# SERDES0 register map
Vendor: Texas Instruments
Peripheral module from a debugger description file (folder am65x).
Registers are 32-bit, read-write, reset 0x0 unless marked. A register's access mark holds for its fields unless they carry their own. Offsets are as the file gives them; lines under a group give offsets from that group; [hi:lo] are bit positions; {n}, {i} and the like mark numbered series; 'fields as' and 'values as' point back to an identical list; <NAME> marks a mode.

## SERDES0 (part 1 of 2)
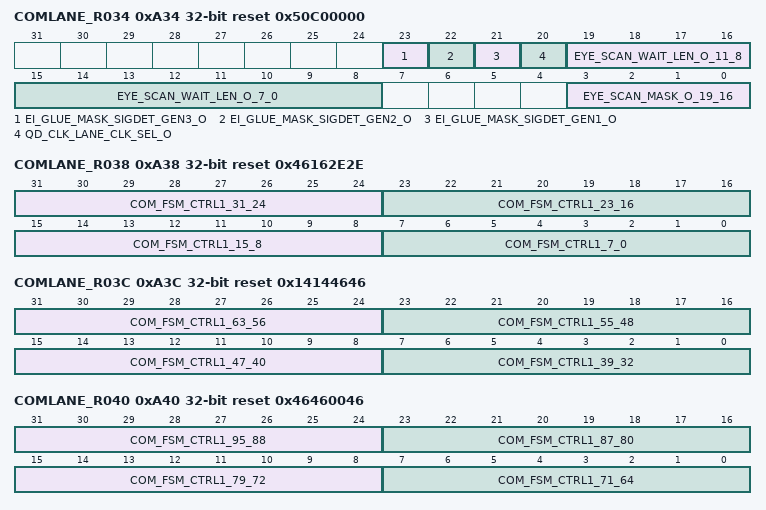
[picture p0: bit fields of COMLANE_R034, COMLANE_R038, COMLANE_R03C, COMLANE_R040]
0xA34 COMLANE_R034 reset 0x50C00000 — The comlane_034 register
  [23] EI_GLUE_MASK_SIGDET_GEN3_O — Mask bits for Gen3 rate for EI Infererence
  [22] EI_GLUE_MASK_SIGDET_GEN2_O — Mask bits for Gen2 rate for EI Infererence
  [21] EI_GLUE_MASK_SIGDET_GEN1_O — Mask bits for Gen1 rate for EI Infererence
  [20] QD_CLK_LANE_CLK_SEL_O — Selects quad clock for Tx Mux 2 and Rx Mux 4
  [19:16] EYE_SCAN_WAIT_LEN_O_11_8 — Eye scan wait time
  [15:8] EYE_SCAN_WAIT_LEN_O_7_0 — Eye scan wait time
  [3:0] EYE_SCAN_MASK_O_19_16 — Mask eye scan results
0xA38 COMLANE_R038 reset 0x46162E2E — The comlane_038 register
  [31:24] COM_FSM_CTRL1_31_24 — COMLANE FSM control 1 register 31-24
  [23:16] COM_FSM_CTRL1_23_16 — COMLANE FSM control 1 register 23-16
  [15:8] COM_FSM_CTRL1_15_8 — COMLANE FSM control 1 register 15-8
  [7:0] COM_FSM_CTRL1_7_0 — COMLANE FSM control 1 register 7-0
0xA3C COMLANE_R03C reset 0x14144646 — The comlane_03c register
  [31:24] COM_FSM_CTRL1_63_56 — COMLANE FSM control 1 register 63-56
  [23:16] COM_FSM_CTRL1_55_48 — COMLANE FSM control 1 register 55-48
  [15:8] COM_FSM_CTRL1_47_40 — COMLANE FSM control 1 register 47-40
  [7:0] COM_FSM_CTRL1_39_32 — COMLANE FSM control 1 register 39-32
0xA40 COMLANE_R040 reset 0x46460046 — The comlane_040 register
  [31:24] COM_FSM_CTRL1_95_88 — COMLANE FSM control 1 register 95-88
  [23:16] COM_FSM_CTRL1_87_80 — COMLANE FSM control 1 register 87-80
  [15:8] COM_FSM_CTRL1_79_72 — COMLANE FSM control 1 register 79-72
  [7:0] COM_FSM_CTRL1_71_64 — COMLANE FSM control 1 register 71-64
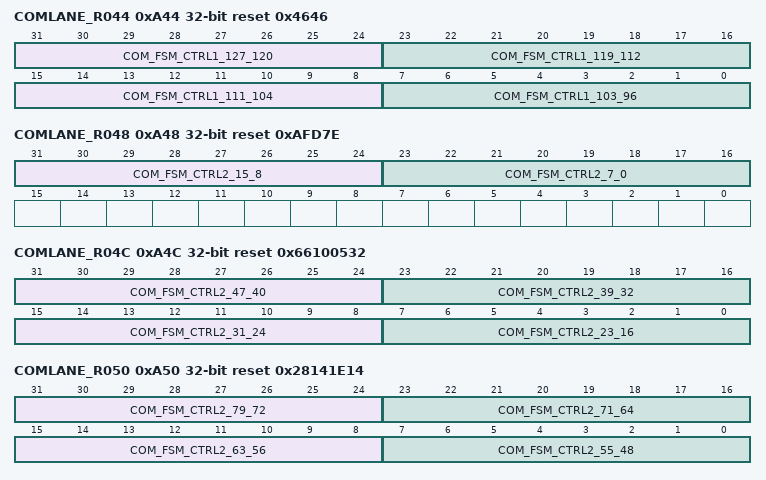
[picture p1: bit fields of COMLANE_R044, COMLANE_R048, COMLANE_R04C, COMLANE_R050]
0xA44 COMLANE_R044 reset 0x4646 — The comlane_044 register
  [31:24] COM_FSM_CTRL1_127_120 — COMLANE FSM control 1 register 127-120
  [23:16] COM_FSM_CTRL1_119_112 — COMLANE FSM control 1 register 119-112
  [15:8] COM_FSM_CTRL1_111_104 — COMLANE FSM control 1 register 111-104
  [7:0] COM_FSM_CTRL1_103_96 — COMLANE FSM control 1 register 103-96
0xA48 COMLANE_R048 reset 0xAFD7E — The comlane_048 register
  [31:24] COM_FSM_CTRL2_15_8 — COMLANE FSM control 2 register [15:8]
  [23:16] COM_FSM_CTRL2_7_0 — COMLANE FSM control 2 register [7:0]
0xA4C COMLANE_R04C reset 0x66100532 — The comlane_04c register
  [31:24] COM_FSM_CTRL2_47_40 — COMLANE FSM control 2 register
  [23:16] COM_FSM_CTRL2_39_32 — COMLANE FSM control 2 register
  [15:8] COM_FSM_CTRL2_31_24 — COMLANE FSM control 2 register
  [7:0] COM_FSM_CTRL2_23_16 — COMLANE FSM control 2 register
0xA50 COMLANE_R050 reset 0x28141E14 — The comlane_050 register
  [31:24] COM_FSM_CTRL2_79_72 — COMLANE FSM control 2 register
  [23:16] COM_FSM_CTRL2_71_64 — COMLANE FSM control 2 register
  [15:8] COM_FSM_CTRL2_63_56 — COMLANE FSM control 2 register
  [7:0] COM_FSM_CTRL2_55_48 — COMLANE FSM control 2 register
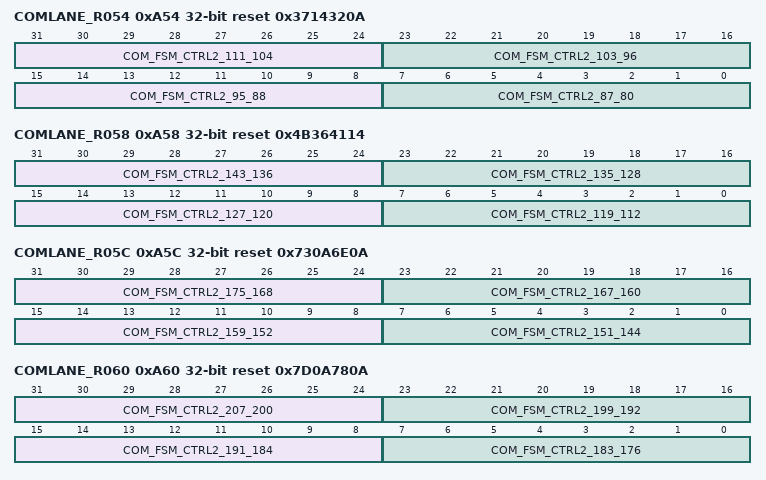
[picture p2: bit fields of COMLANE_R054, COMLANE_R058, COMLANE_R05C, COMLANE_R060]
0xA54 COMLANE_R054 reset 0x3714320A — The comlane_054 register
  [31:24] COM_FSM_CTRL2_111_104 — COMLANE FSM control 2 register
  [23:16] COM_FSM_CTRL2_103_96 — COMLANE FSM control 2 register
  [15:8] COM_FSM_CTRL2_95_88 — COMLANE FSM control 2 register
  [7:0] COM_FSM_CTRL2_87_80 — COMLANE FSM control 2 register
0xA58 COMLANE_R058 reset 0x4B364114 — The comlane_058 register
  [31:24] COM_FSM_CTRL2_143_136 — COMLANE FSM control 2 register
  [23:16] COM_FSM_CTRL2_135_128 — COMLANE FSM control 2 register
  [15:8] COM_FSM_CTRL2_127_120 — COMLANE FSM control 2 register
  [7:0] COM_FSM_CTRL2_119_112 — COMLANE FSM control 2 register
0xA5C COMLANE_R05C reset 0x730A6E0A — The comlane_05c register
  [31:24] COM_FSM_CTRL2_175_168 — COMLANE FSM control 2 register
  [23:16] COM_FSM_CTRL2_167_160 — COMLANE FSM control 2 register
  [15:8] COM_FSM_CTRL2_159_152 — COMLANE FSM control 2 register
  [7:0] COM_FSM_CTRL2_151_144 — COMLANE FSM control 2 register
0xA60 COMLANE_R060 reset 0x7D0A780A — The comlane_060 register
  [31:24] COM_FSM_CTRL2_207_200 — COMLANE FSM control 2 register
  [23:16] COM_FSM_CTRL2_199_192 — COMLANE FSM control 2 register
  [15:8] COM_FSM_CTRL2_191_184 — COMLANE FSM control 2 register
  [7:0] COM_FSM_CTRL2_183_176 — COMLANE FSM control 2 register
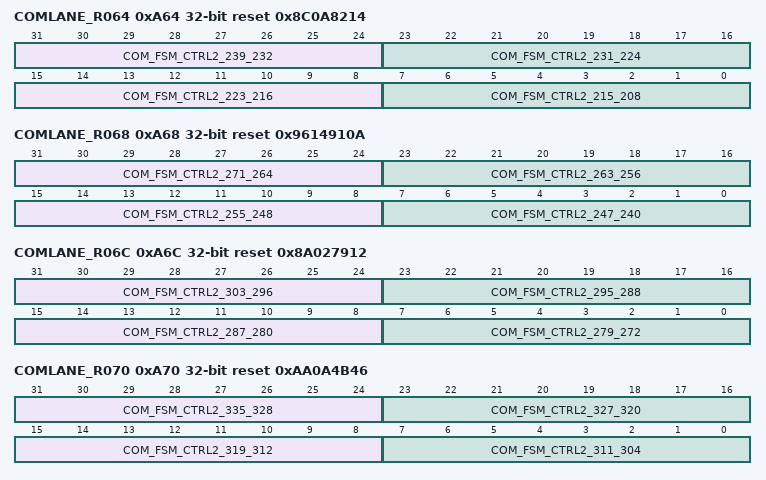
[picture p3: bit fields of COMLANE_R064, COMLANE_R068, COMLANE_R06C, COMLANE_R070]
0xA64 COMLANE_R064 reset 0x8C0A8214 — The comlane_064 register
  [31:24] COM_FSM_CTRL2_239_232 — COMLANE FSM control 2 register
  [23:16] COM_FSM_CTRL2_231_224 — COMLANE FSM control 2 register
  [15:8] COM_FSM_CTRL2_223_216 — COMLANE FSM control 2 register
  [7:0] COM_FSM_CTRL2_215_208 — COMLANE FSM control 2 register
0xA68 COMLANE_R068 reset 0x9614910A — The comlane_068 register
  [31:24] COM_FSM_CTRL2_271_264 — COMLANE FSM control 2 register
  [23:16] COM_FSM_CTRL2_263_256 — COMLANE FSM control 2 register
  [15:8] COM_FSM_CTRL2_255_248 — COMLANE FSM control 2 register
  [7:0] COM_FSM_CTRL2_247_240 — COMLANE FSM control 2 register
0xA6C COMLANE_R06C reset 0x8A027912 — The comlane_06c register
  [31:24] COM_FSM_CTRL2_303_296 — COMLANE FSM control 2 register
  [23:16] COM_FSM_CTRL2_295_288 — COMLANE FSM control 2 register
  [15:8] COM_FSM_CTRL2_287_280 — COMLANE FSM control 2 register
  [7:0] COM_FSM_CTRL2_279_272 — COMLANE FSM control 2 register
0xA70 COMLANE_R070 reset 0xAA0A4B46 — The comlane_070 register
  [31:24] COM_FSM_CTRL2_335_328 — COMLANE FSM control 2 register
  [23:16] COM_FSM_CTRL2_327_320 — COMLANE FSM control 2 register
  [15:8] COM_FSM_CTRL2_319_312 — COMLANE FSM control 2 register
  [7:0] COM_FSM_CTRL2_311_304 — COMLANE FSM control 2 register
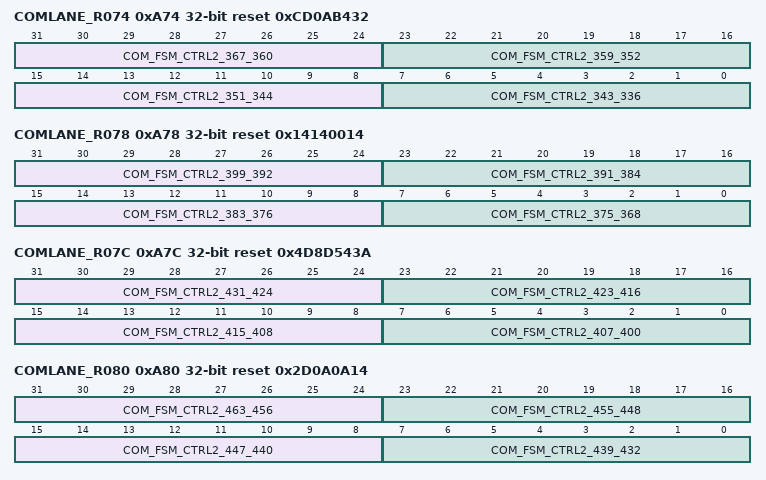
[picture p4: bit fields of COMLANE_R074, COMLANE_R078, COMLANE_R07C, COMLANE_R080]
0xA74 COMLANE_R074 reset 0xCD0AB432 — The comlane_074 register
  [31:24] COM_FSM_CTRL2_367_360 — COMLANE FSM control 2 register
  [23:16] COM_FSM_CTRL2_359_352 — COMLANE FSM control 2 register
  [15:8] COM_FSM_CTRL2_351_344 — COMLANE FSM control 2 register
  [7:0] COM_FSM_CTRL2_343_336 — COMLANE FSM control 2 register
0xA78 COMLANE_R078 reset 0x14140014 — The comlane_078 register
  [31:24] COM_FSM_CTRL2_399_392 — COMLANE FSM control 2 register
  [23:16] COM_FSM_CTRL2_391_384 — COMLANE FSM control 2 register
  [15:8] COM_FSM_CTRL2_383_376 — COMLANE FSM control 2 register
  [7:0] COM_FSM_CTRL2_375_368 — COMLANE FSM control 2 register
0xA7C COMLANE_R07C reset 0x4D8D543A — The comlane_07c register
  [31:24] COM_FSM_CTRL2_431_424 — COMLANE FSM control 2 register
  [23:16] COM_FSM_CTRL2_423_416 — COMLANE FSM control 2 register
  [15:8] COM_FSM_CTRL2_415_408 — COMLANE FSM control 2 register
  [7:0] COM_FSM_CTRL2_407_400 — COMLANE FSM control 2 register
0xA80 COMLANE_R080 reset 0x2D0A0A14 — The comlane_080 register
  [31:24] COM_FSM_CTRL2_463_456 — COMLANE FSM control 2 register
  [23:16] COM_FSM_CTRL2_455_448 — COMLANE FSM control 2 register
  [15:8] COM_FSM_CTRL2_447_440 — COMLANE FSM control 2 register
  [7:0] COM_FSM_CTRL2_439_432 — COMLANE FSM control 2 register
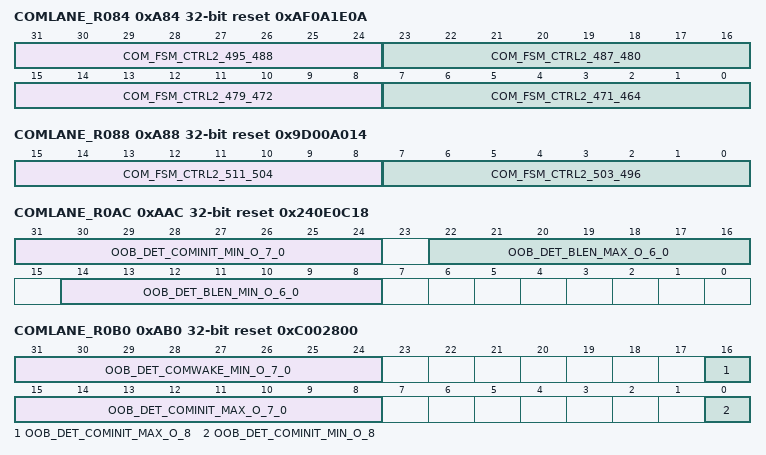
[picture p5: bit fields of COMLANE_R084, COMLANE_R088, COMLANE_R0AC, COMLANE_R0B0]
0xA84 COMLANE_R084 reset 0xAF0A1E0A — The comlane_084 register
  [31:24] COM_FSM_CTRL2_495_488 — COMLANE FSM control 2 register
  [23:16] COM_FSM_CTRL2_487_480 — COMLANE FSM control 2 register
  [15:8] COM_FSM_CTRL2_479_472 — COMLANE FSM control 2 register
  [7:0] COM_FSM_CTRL2_471_464 — COMLANE FSM control 2 register
0xA88 COMLANE_R088 reset 0x9D00A014 — The comlane_088 register
  [15:8] COM_FSM_CTRL2_511_504 — COMLANE FSM control 2 register
  [7:0] COM_FSM_CTRL2_503_496 — COMLANE FSM control 2 register
0xAAC COMLANE_R0AC reset 0x240E0C18 — The comlane_0ac register
  [31:24] OOB_DET_COMINIT_MIN_O_7_0 — OOB detector COMINIT maximum idle length.
  [22:16] OOB_DET_BLEN_MAX_O_6_0 — OOB detector maximum burst length.
  [14:8] OOB_DET_BLEN_MIN_O_6_0 — OOB detector minimum burst length.
0xAB0 COMLANE_R0B0 reset 0xC002800 — The comlane_0b0 register
  [31:24] OOB_DET_COMWAKE_MIN_O_7_0 — OOB detector COMWAKE minimum idle length.
  [16] OOB_DET_COMINIT_MAX_O_8 — OOB detector COMINIT maximum idle length.
  [15:8] OOB_DET_COMINIT_MAX_O_7_0 — OOB detector COMINIT maximum idle length.
  [0] OOB_DET_COMINIT_MIN_O_8 — OOB detector COMINIT maximum idle length.
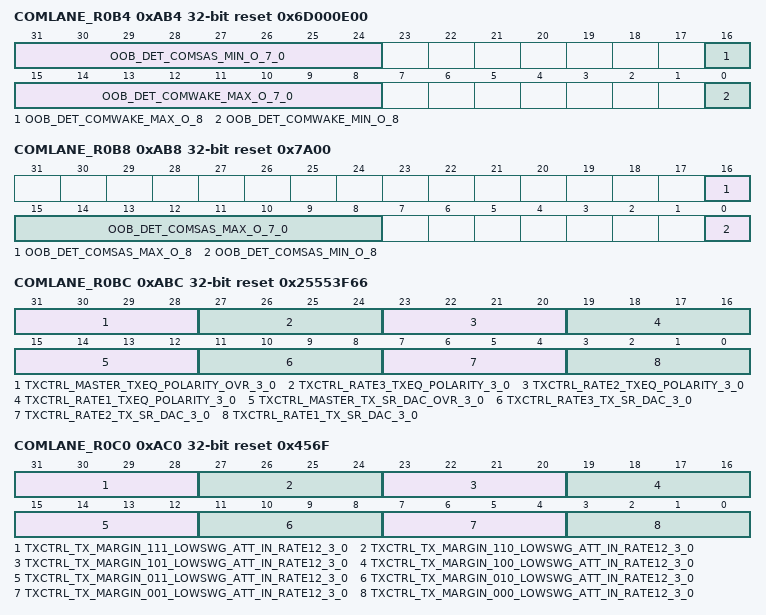
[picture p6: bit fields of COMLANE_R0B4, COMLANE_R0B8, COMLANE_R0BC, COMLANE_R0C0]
0xAB4 COMLANE_R0B4 reset 0x6D000E00 — The comlane_0b4 register
  [31:24] OOB_DET_COMSAS_MIN_O_7_0 — OOB detector COMSAS maximum idle length.
  [16] OOB_DET_COMWAKE_MAX_O_8 — OOB detector COMWAKE maximum idle length.
  [15:8] OOB_DET_COMWAKE_MAX_O_7_0 — OOB detector COMWAKE maximum idle length.
  [0] OOB_DET_COMWAKE_MIN_O_8 — OOB detector COMWAKE minimum idle length.
0xAB8 COMLANE_R0B8 reset 0x7A00 — The comlane_0b8 register
  [16] OOB_DET_COMSAS_MAX_O_8 — OOB detector COMSAS maximum idle length.
  [15:8] OOB_DET_COMSAS_MAX_O_7_0 — OOB detector COMSAS maximum idle length.
  [0] OOB_DET_COMSAS_MIN_O_8 — OOB detector COMSAS maximum idle length.
0xABC COMLANE_R0BC reset 0x25553F66 — The comlane_0bc register
  [31:28] TXCTRL_MASTER_TXEQ_POLARITY_OVR_3_0 — TX master coefficient polarity overrides.
  [27:24] TXCTRL_RATE3_TXEQ_POLARITY_3_0 — TX rate3 coefficent polarity
  [23:20] TXCTRL_RATE2_TXEQ_POLARITY_3_0 — TX rate2 coefficent polarity
  [19:16] TXCTRL_RATE1_TXEQ_POLARITY_3_0 — TX rate1 coefficent polarity
  [15:12] TXCTRL_MASTER_TX_SR_DAC_OVR_3_0 — TX master slew rate DAC overrides
  [11:8] TXCTRL_RATE3_TX_SR_DAC_3_0 — TX rate3 slew rate DAC setting
  [7:4] TXCTRL_RATE2_TX_SR_DAC_3_0 — TX rate2 slew rate DAC setting
  [3:0] TXCTRL_RATE1_TX_SR_DAC_3_0 — TX rate1 slew rate DAC setting
0xAC0 COMLANE_R0C0 reset 0x456F — The comlane_0c0 register
  [31:28] TXCTRL_TX_MARGIN_111_LOWSWG_ATT_IN_RATE12_3_0 — PIPE tx_margin low swing setting
  [27:24] TXCTRL_TX_MARGIN_110_LOWSWG_ATT_IN_RATE12_3_0 — PIPE tx_margin low swing setting
  [23:20] TXCTRL_TX_MARGIN_101_LOWSWG_ATT_IN_RATE12_3_0 — PIPE tx_margin low swing setting
  [19:16] TXCTRL_TX_MARGIN_100_LOWSWG_ATT_IN_RATE12_3_0 — PIPE tx_margin low swing setting
  [15:12] TXCTRL_TX_MARGIN_011_LOWSWG_ATT_IN_RATE12_3_0 — PIPE tx_margin low swing setting
  [11:8] TXCTRL_TX_MARGIN_010_LOWSWG_ATT_IN_RATE12_3_0 — PIPE tx_margin low swing setting
  [7:4] TXCTRL_TX_MARGIN_001_LOWSWG_ATT_IN_RATE12_3_0 — PIPE tx_margin low swing setting
  [3:0] TXCTRL_TX_MARGIN_000_LOWSWG_ATT_IN_RATE12_3_0 — PIPE tx_margin low swing setting
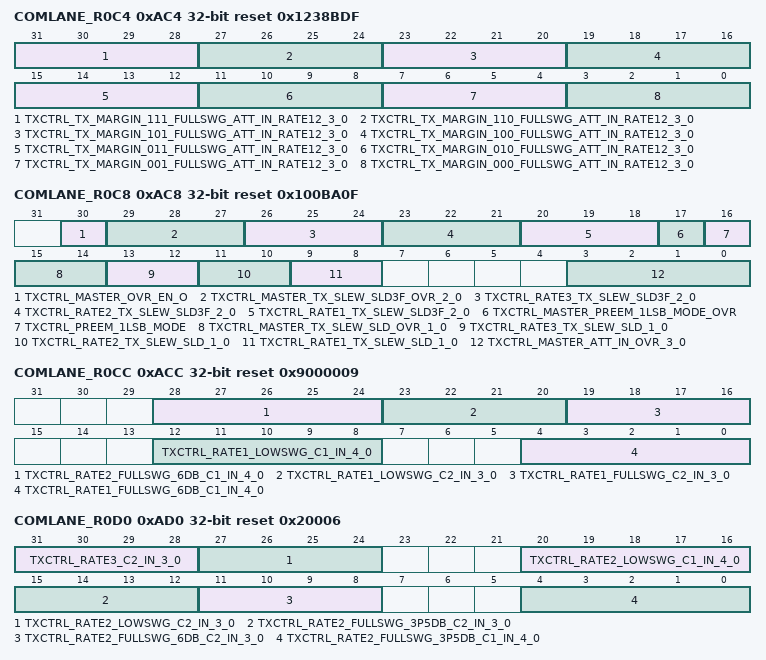
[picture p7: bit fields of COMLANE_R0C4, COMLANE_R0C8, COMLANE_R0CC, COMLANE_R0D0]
0xAC4 COMLANE_R0C4 reset 0x1238BDF — The comlane_0c4 register
  [31:28] TXCTRL_TX_MARGIN_111_FULLSWG_ATT_IN_RATE12_3_0 — PIPE tx_margin full swing setting
  [27:24] TXCTRL_TX_MARGIN_110_FULLSWG_ATT_IN_RATE12_3_0 — PIPE tx_margin full swing setting
  [23:20] TXCTRL_TX_MARGIN_101_FULLSWG_ATT_IN_RATE12_3_0 — PIPE tx_margin full swing setting
  [19:16] TXCTRL_TX_MARGIN_100_FULLSWG_ATT_IN_RATE12_3_0 — PIPE tx_margin full swing setting
  [15:12] TXCTRL_TX_MARGIN_011_FULLSWG_ATT_IN_RATE12_3_0 — PIPE tx_margin full swing setting
  [11:8] TXCTRL_TX_MARGIN_010_FULLSWG_ATT_IN_RATE12_3_0 — PIPE tx_margin full swing setting
  [7:4] TXCTRL_TX_MARGIN_001_FULLSWG_ATT_IN_RATE12_3_0 — PIPE tx_margin full swing setting
  [3:0] TXCTRL_TX_MARGIN_000_FULLSWG_ATT_IN_RATE12_3_0 — PIPE tx_margin full swing setting
0xAC8 COMLANE_R0C8 reset 0x100BA0F — The comlane_0c8 register
  [30] TXCTRL_MASTER_OVR_EN_O — Tx control master override enable
  [29:27] TXCTRL_MASTER_TX_SLEW_SLD3F_OVR_2_0 — TX enable fastest slew rate override.
  [26:24] TXCTRL_RATE3_TX_SLEW_SLD3F_2_0 — TX enable fastest slew rate set to 1.
  [23:21] TXCTRL_RATE2_TX_SLEW_SLD3F_2_0 — TX enable fastest slew rate set to 1.
  [20:18] TXCTRL_RATE1_TX_SLEW_SLD3F_2_0 — TX enable fastest slew rate set to 1.
  [17] TXCTRL_MASTER_PREEM_1LSB_MODE_OVR — TX master 1lsb mode overrides.
  [16] TXCTRL_PREEM_1LSB_MODE — TX 1lsb mode
  [15:14] TXCTRL_MASTER_TX_SLEW_SLD_OVR_1_0 — TX master slew rate setting overrides.
  [13:12] TXCTRL_RATE3_TX_SLEW_SLD_1_0 — TX rate3 slew rate setting
  [11:10] TXCTRL_RATE2_TX_SLEW_SLD_1_0 — TX rate2 slew rate setting
  [9:8] TXCTRL_RATE1_TX_SLEW_SLD_1_0 — TX rate1 slew rate setting
  [3:0] TXCTRL_MASTER_ATT_IN_OVR_3_0 — Override value for att in.
0xACC COMLANE_R0CC reset 0x9000009 — The comlane_0cc register
  [28:24] TXCTRL_RATE2_FULLSWG_6DB_C1_IN_4_0 — TX rate2 full swing C1 coefficient for 6 dB
  [23:20] TXCTRL_RATE1_LOWSWG_C2_IN_3_0 — TX rate1 low swing C2 coefficient
  [19:16] TXCTRL_RATE1_FULLSWG_C2_IN_3_0 — TX rate1 full swing C2 coefficient
  [12:8] TXCTRL_RATE1_LOWSWG_C1_IN_4_0 — TX rate1 low swing C1 coefficient
  [4:0] TXCTRL_RATE1_FULLSWG_6DB_C1_IN_4_0 — TX rate1 full swing C1 coefficient
0xAD0 COMLANE_R0D0 reset 0x20006 — The comlane_0d0 register
  [31:28] TXCTRL_RATE3_C2_IN_3_0 — TX rate3 C2 coefficient
  [27:24] TXCTRL_RATE2_LOWSWG_C2_IN_3_0 — TX rate2 low swing C2 coefficient for 6 dB
  [20:16] TXCTRL_RATE2_LOWSWG_C1_IN_4_0 — TX rate2 low swing C1 coefficient for 6 dB
  [15:12] TXCTRL_RATE2_FULLSWG_3P5DB_C2_IN_3_0 — TX rate2 full swing C2 coefficient for 3.5 dB
  [11:8] TXCTRL_RATE2_FULLSWG_6DB_C2_IN_3_0 — TX rate2 full swing C2 coefficient for 6 dB
  [4:0] TXCTRL_RATE2_FULLSWG_3P5DB_C1_IN_4_0 — TX rate2 full swing C1 coefficient for 3.5 dB
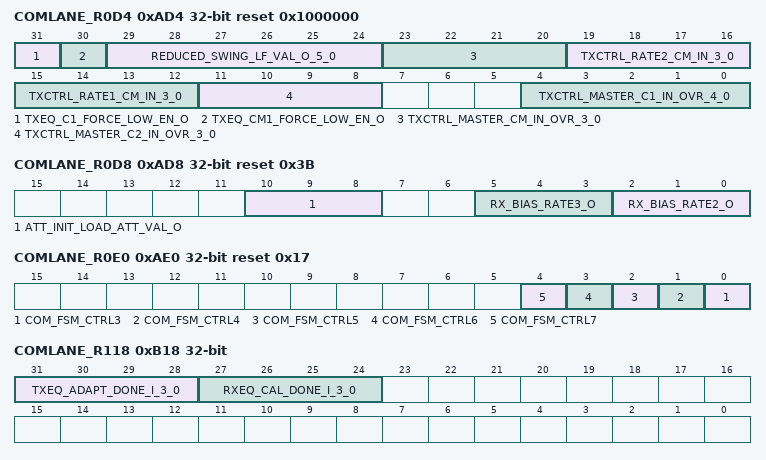
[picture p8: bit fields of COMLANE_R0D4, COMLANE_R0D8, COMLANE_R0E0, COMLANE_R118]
0xAD4 COMLANE_R0D4 reset 0x1000000 — The comlane_0d4 register
  [31] TXEQ_C1_FORCE_LOW_EN_O — Brings the TxEq pre-cursor down to a programmable value txeq_c1_min_limit if pre cursor tuning is bypassed
  [30] TXEQ_CM1_FORCE_LOW_EN_O — Brings the TxEq pre-cursor down to a programmable value txeq_cm1_min_limit if pre cursor tuning is bypassed
  [29:24] REDUCED_SWING_LF_VAL_O_5_0 — Reduced swing LowFreq value
  [23:20] TXCTRL_MASTER_CM_IN_OVR_3_0 — TX master CM coefficient overrides.
  [19:16] TXCTRL_RATE2_CM_IN_3_0 — TX rate2 CM coefficient
  [15:12] TXCTRL_RATE1_CM_IN_3_0 — TX rate1 CM coefficient
  [11:8] TXCTRL_MASTER_C2_IN_OVR_3_0 — TX master C2 coefficient overrides.
  [4:0] TXCTRL_MASTER_C1_IN_OVR_4_0 — TX master C1 coefficient overrides.
0xAD8 COMLANE_R0D8 reset 0x3B — The comlane_0d8 register
  [10:8] ATT_INIT_LOAD_ATT_VAL_O — AGC initial ATT value
  [5:3] RX_BIAS_RATE3_O — AFE rx_bias setting. Used when rxvcodiv is 01 or 10
  [2:0] RX_BIAS_RATE2_O — AFE rx_bias setting. Used when rxvcodiv is 00
0xAE0 COMLANE_R0E0 reset 0x17 — The comlane_0e0 register
  [n-3] COM_FSM_CTRL{n} (n=3..7) — COMLANE FSM control {n} register
0xAFC COMLANE_R0FC (reset mask 0x1F00FFFF) — The comlane_0fc register
0xB04 COMLANE_R104 — The comlane_104 register
  [31:30] ATT_INIT_LOAD_GAIN_VAL_O — Initial AGC gain value
0xB14 COMLANE_R114 reset 0x14A (reset mask 0xFFFF) — The comlane_114 register
0xB18 COMLANE_R118 ro — The comlane_118 register
  [31:28] TXEQ_ADAPT_DONE_I_3_0 — TXEQ Adapt Done status - per lane
  [27:24] RXEQ_CAL_DONE_I_3_0 — RXEQ calibration done status - per lane
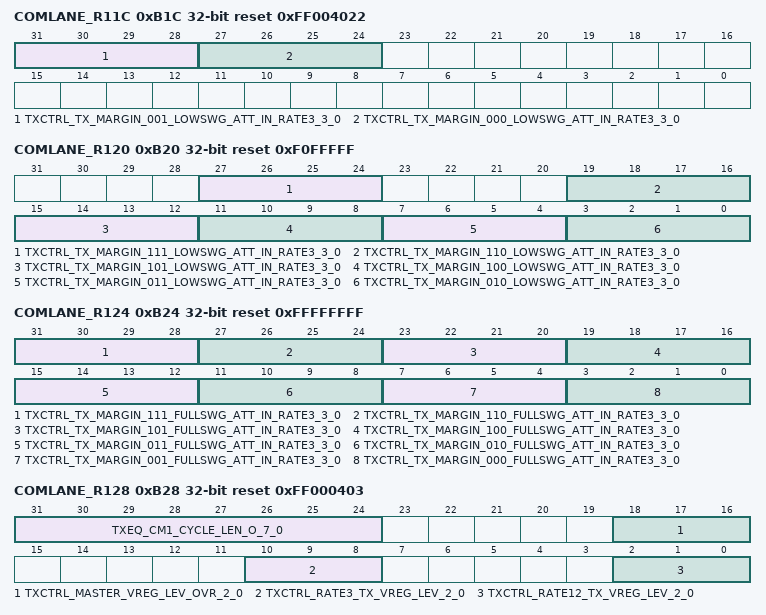
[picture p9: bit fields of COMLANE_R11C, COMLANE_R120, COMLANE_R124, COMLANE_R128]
0xB1C COMLANE_R11C reset 0xFF004022 — The comlane_11c register
  [31:28] TXCTRL_TX_MARGIN_001_LOWSWG_ATT_IN_RATE3_3_0 — PIPE tx_margin low swing setting rate3
  [27:24] TXCTRL_TX_MARGIN_000_LOWSWG_ATT_IN_RATE3_3_0 — PIPE tx_margin low swing setting rate3
0xB20 COMLANE_R120 reset 0xF0FFFFF — The comlane_120 register
  [27:24] TXCTRL_TX_MARGIN_111_LOWSWG_ATT_IN_RATE3_3_0 — PIPE tx_margin low swing setting rate3
  [19:16] TXCTRL_TX_MARGIN_110_LOWSWG_ATT_IN_RATE3_3_0 — PIPE tx_margin low swing setting rate3
  [15:12] TXCTRL_TX_MARGIN_101_LOWSWG_ATT_IN_RATE3_3_0 — PIPE tx_margin low swing setting rate3
  [11:8] TXCTRL_TX_MARGIN_100_LOWSWG_ATT_IN_RATE3_3_0 — PIPE tx_margin low swing setting rate3
  [7:4] TXCTRL_TX_MARGIN_011_LOWSWG_ATT_IN_RATE3_3_0 — PIPE tx_margin low swing setting rate3
  [3:0] TXCTRL_TX_MARGIN_010_LOWSWG_ATT_IN_RATE3_3_0 — PIPE tx_margin low swing setting rate3
0xB24 COMLANE_R124 reset 0xFFFFFFFF — The comlane_124 register
  [31:28] TXCTRL_TX_MARGIN_111_FULLSWG_ATT_IN_RATE3_3_0 — PIPE tx_margin full swing setting rate3
  [27:24] TXCTRL_TX_MARGIN_110_FULLSWG_ATT_IN_RATE3_3_0 — PIPE tx_margin full swing setting rate3
  [23:20] TXCTRL_TX_MARGIN_101_FULLSWG_ATT_IN_RATE3_3_0 — PIPE tx_margin full swing setting rate3
  [19:16] TXCTRL_TX_MARGIN_100_FULLSWG_ATT_IN_RATE3_3_0 — PIPE tx_margin full swing setting rate3
  [15:12] TXCTRL_TX_MARGIN_011_FULLSWG_ATT_IN_RATE3_3_0 — PIPE tx_margin full swing setting rate3
  [11:8] TXCTRL_TX_MARGIN_010_FULLSWG_ATT_IN_RATE3_3_0 — PIPE tx_margin full swing setting rate3
  [7:4] TXCTRL_TX_MARGIN_001_FULLSWG_ATT_IN_RATE3_3_0 — PIPE tx_margin full swing setting rate3
  [3:0] TXCTRL_TX_MARGIN_000_FULLSWG_ATT_IN_RATE3_3_0 — PIPE tx_margin full swing setting rate3
0xB28 COMLANE_R128 reset 0xFF000403 — The comlane_128 register
  [31:24] TXEQ_CM1_CYCLE_LEN_O_7_0 — Txeq CM1 coefficient adpatation error measurment wait time during each iteration
  [18:16] TXCTRL_MASTER_VREG_LEV_OVR_2_0 — Does not exist!
  [10:8] TXCTRL_RATE3_TX_VREG_LEV_2_0 — TX driver regulator voltage setting.
  [2:0] TXCTRL_RATE12_TX_VREG_LEV_2_0 — TX driver regulator voltage setting.
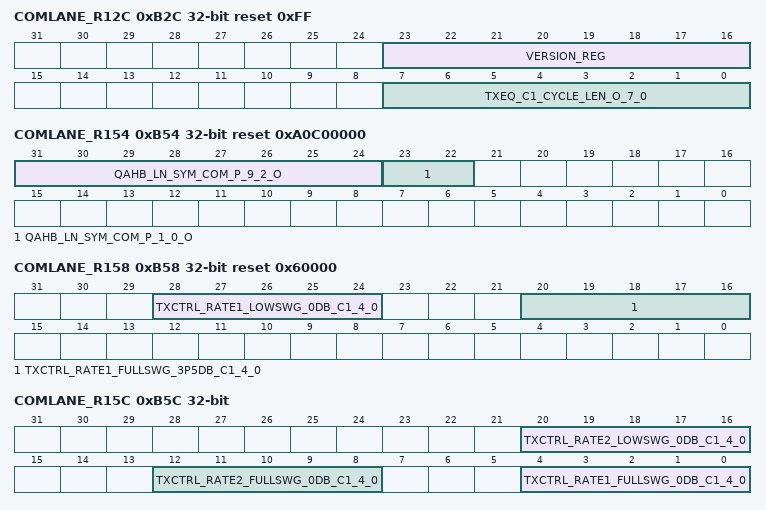
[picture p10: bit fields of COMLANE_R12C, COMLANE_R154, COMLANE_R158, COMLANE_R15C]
0xB2C COMLANE_R12C access per field reset 0xFF — The comlane_12c register
  [23:16] VERSION_REG ro — Version register
  [7:0] TXEQ_C1_CYCLE_LEN_O_7_0 rw — Txeq C1 coefficient adpatation error measurment wait time during each iteration
0xB38 COMLANE_R138 reset 0x3827 — The comlane_138 register
  [23:16] CONFIG_VERSION_REG — Config files write their version into these registers
0xB54 COMLANE_R154 reset 0xA0C00000 — The comlane_154 register
  [31:24] QAHB_LN_SYM_COM_P_9_2_O — COM symbol for LB_BERT
  [23:22] QAHB_LN_SYM_COM_P_1_0_O — COM symbol for LB_BERT
0xB58 COMLANE_R158 reset 0x60000 — The comlane_158 register
  [28:24] TXCTRL_RATE1_LOWSWG_0DB_C1_4_0 — TX rate1 low swing C1 coefficient 0db
  [20:16] TXCTRL_RATE1_FULLSWG_3P5DB_C1_4_0 — TX rate1 full swing C1 coefficient 3.5db
0xB5C COMLANE_R15C — The comlane_15c register
  [20:16] TXCTRL_RATE2_LOWSWG_0DB_C1_4_0 — TX rate2 low swing C1 coefficient 0 db
  [12:8] TXCTRL_RATE2_FULLSWG_0DB_C1_4_0 — TX rate2 full swing C1 coefficient 0db
  [4:0] TXCTRL_RATE1_FULLSWG_0DB_C1_4_0 — TX rate1 full swing C1 coefficient 0db
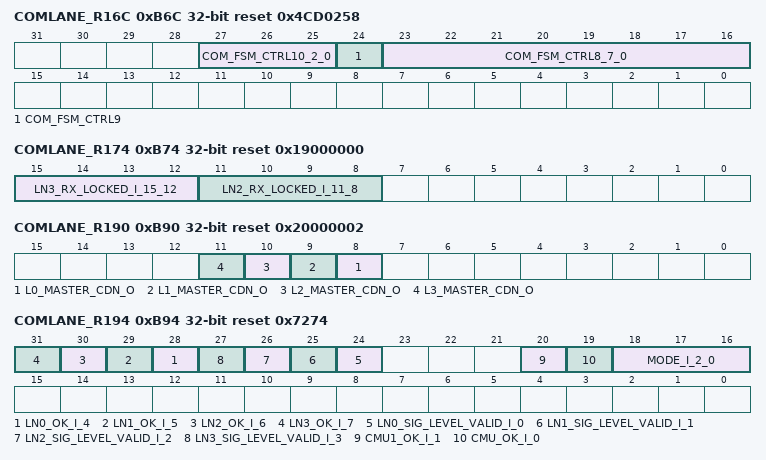
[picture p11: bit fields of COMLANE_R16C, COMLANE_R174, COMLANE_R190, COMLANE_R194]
0xB6C COMLANE_R16C reset 0x4CD0258 — The comlane_16c register
  [27:25] COM_FSM_CTRL10_2_0 — COMLANE FSM control 10 register [2:0]
  [24] COM_FSM_CTRL9 — COMLANE FSM control 9 register
  [23:16] COM_FSM_CTRL8_7_0 — COMLANE FSM control 8 register [7:0]
0xB74 COMLANE_R174 access per field reset 0x19000000 — The comlane_174 register
  [15:12] LN3_RX_LOCKED_I_15_12 ro — Lane 3 RX Locked status
  [11:8] LN2_RX_LOCKED_I_11_8 ro — Lane 2 RX Locked status
0xB90 COMLANE_R190 reset 0x20000002 — The comlane_190 register
  [n+8] L{n}_MASTER_CDN_O (n=0..3) — Lane{n} master reset
0xB94 COMLANE_R194 access per field reset 0x7274 — The comlane_194 register
  [n+28] LN{n}_OK_I_{n+4} ro (n=0..3) — Lane {n} OK Status
  [n+24] LN{n}_SIG_LEVEL_VALID_I_{n} ro (n=0..3) — Lane {n} Signal Detect Valid Status
  [20] CMU1_OK_I_1 ro — CMU1 OK Status
  [19] CMU_OK_I_0 ro — CMU OK Status
  [18:16] MODE_I_2_0 ro — 1000Base-KX Mode status for CPU
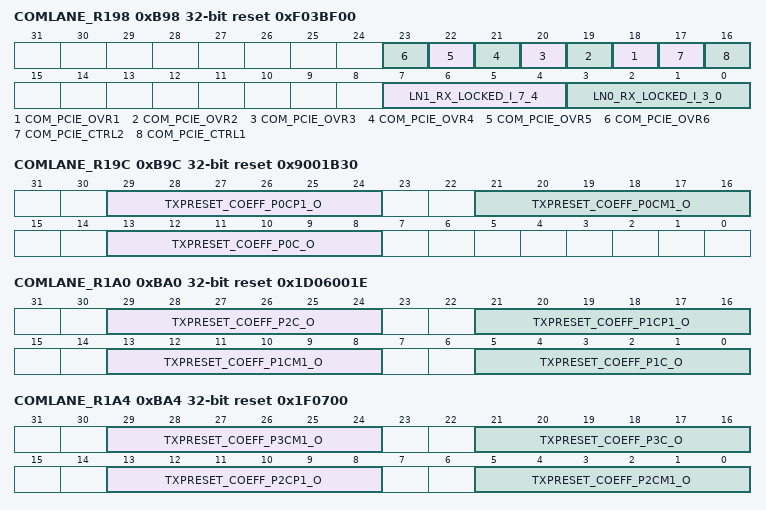
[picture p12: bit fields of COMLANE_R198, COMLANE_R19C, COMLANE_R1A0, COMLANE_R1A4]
0xB98 COMLANE_R198 access per field reset 0xF03BF00 — The comlane_198 register
  [n+17] COM_PCIE_OVR{n} rw (n=1..6) — COMLANE PCIe override {n} register
  [17] COM_PCIE_CTRL2 rw — COMLANE PCIe control 2 register
  [16] COM_PCIE_CTRL1 rw — COMLANE PCIe control 1 register
  [7:4] LN1_RX_LOCKED_I_7_4 ro — Lane 1 RX Locked Status
  [3:0] LN0_RX_LOCKED_I_3_0 ro — Lane 0 RX Locked status
0xB9C COMLANE_R19C reset 0x9001B30 — The comlane_19c register
  [29:24] TXPRESET_COEFF_P0CP1_O — txpreset_coeff P0 C+1
  [21:16] TXPRESET_COEFF_P0CM1_O — txpreset_coeff P0 C-1
  [13:8] TXPRESET_COEFF_P0C_O — txpreset_coeff P0 C
0xBA0 COMLANE_R1A0 reset 0x1D06001E — The comlane_1a0 register
  [29:24] TXPRESET_COEFF_P2C_O — txpreset_coeff P2 C
  [21:16] TXPRESET_COEFF_P1CP1_O — txpreset_coeff P1 C+1
  [13:8] TXPRESET_COEFF_P1CM1_O — txpreset_coeff P1 C-1
  [5:0] TXPRESET_COEFF_P1C_O — txpreset_coeff P1 C
0xBA4 COMLANE_R1A4 reset 0x1F0700 — The comlane_1a4 register
  [29:24] TXPRESET_COEFF_P3CM1_O — txpreset_coeff P3 C-1
  [21:16] TXPRESET_COEFF_P3C_O — txpreset_coeff P3 C
  [13:8] TXPRESET_COEFF_P2CP1_O — txpreset_coeff P2 C+1
  [5:0] TXPRESET_COEFF_P2CM1_O — txpreset_coeff P2 C-1
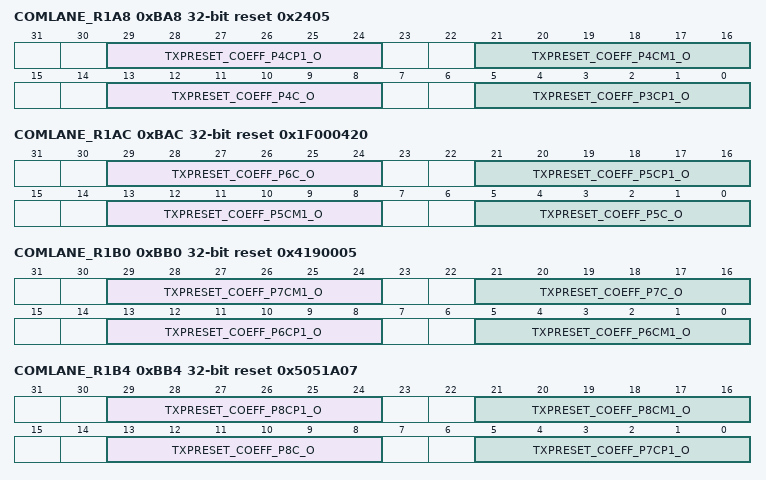
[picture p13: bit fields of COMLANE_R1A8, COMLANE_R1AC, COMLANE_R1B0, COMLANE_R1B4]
0xBA8 COMLANE_R1A8 reset 0x2405 — The comlane_1a8 register
  [29:24] TXPRESET_COEFF_P4CP1_O — txpreset_coeff P4 C+1
  [21:16] TXPRESET_COEFF_P4CM1_O — txpreset_coeff P4 C-1
  [13:8] TXPRESET_COEFF_P4C_O — txpreset_coeff P4 C
  [5:0] TXPRESET_COEFF_P3CP1_O — txpreset_coeff P3 C+1
0xBAC COMLANE_R1AC reset 0x1F000420 — The comlane_1ac register
  [29:24] TXPRESET_COEFF_P6C_O — txpreset_coeff P6 C
  [21:16] TXPRESET_COEFF_P5CP1_O — txpreset_coeff P5 C+1
  [13:8] TXPRESET_COEFF_P5CM1_O — txpreset_coeff P5 C-1
  [5:0] TXPRESET_COEFF_P5C_O — txpreset_coeff P5 C
0xBB0 COMLANE_R1B0 reset 0x4190005 — The comlane_1b0 register
  [29:24] TXPRESET_COEFF_P7CM1_O — txpreset_coeff P7 C-1
  [21:16] TXPRESET_COEFF_P7C_O — txpreset_coeff P7 C
  [13:8] TXPRESET_COEFF_P6CP1_O — txpreset_coeff P6 C+1
  [5:0] TXPRESET_COEFF_P6CM1_O — txpreset_coeff P6 C-1
0xBB4 COMLANE_R1B4 reset 0x5051A07 — The comlane_1b4 register
  [29:24] TXPRESET_COEFF_P8CP1_O — txpreset_coeff P8 C+1
  [21:16] TXPRESET_COEFF_P8CM1_O — txpreset_coeff P8 C-1
  [13:8] TXPRESET_COEFF_P8C_O — txpreset_coeff P8 C
  [5:0] TXPRESET_COEFF_P7CP1_O — txpreset_coeff P7 C+1
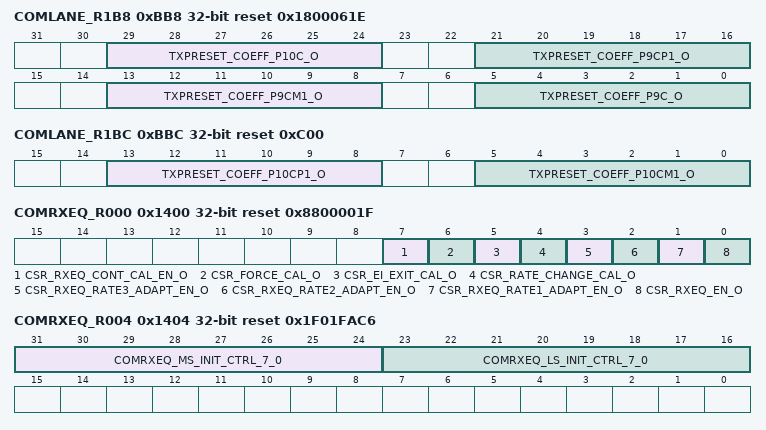
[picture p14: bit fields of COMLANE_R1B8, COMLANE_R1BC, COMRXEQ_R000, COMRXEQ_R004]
0xBB8 COMLANE_R1B8 reset 0x1800061E — The comlane_1b8 register
  [29:24] TXPRESET_COEFF_P10C_O — txpreset_coeff P10 C
  [21:16] TXPRESET_COEFF_P9CP1_O — txpreset_coeff P9 C+1
  [13:8] TXPRESET_COEFF_P9CM1_O — txpreset_coeff P9 C-1
  [5:0] TXPRESET_COEFF_P9C_O — txpreset_coeff P9 C
0xBBC COMLANE_R1BC reset 0xC00 — The comlane_1bc register
  [13:8] TXPRESET_COEFF_P10CP1_O — txpreset_coeff P10 C+1
  [5:0] TXPRESET_COEFF_P10CM1_O — txpreset_coeff P10 C-1
0x1400 COMRXEQ_R000 reset 0x8800001F — The comrxeq_000 register
  [7] CSR_RXEQ_CONT_CAL_EN_O — This register enables continuous time rxeq adaptation in the background
  [6] CSR_FORCE_CAL_O — This register forces one round of rxeq run
  [5] CSR_EI_EXIT_CAL_O — This register controls whether to perform any adaptation during electrical idle exit or not.
  [4] CSR_RATE_CHANGE_CAL_O — This register controls whether to perform any adaptation during rate change or not.
  [3] CSR_RXEQ_RATE3_ADAPT_EN_O — This is the master enable for all adaptations in RATE3.
  [2] CSR_RXEQ_RATE2_ADAPT_EN_O — This is the master enable for all adaptations in RATE2.
  [1] CSR_RXEQ_RATE1_ADAPT_EN_O — This is the master enable for all adaptations in RATE1
  [0] CSR_RXEQ_EN_O — Master enable for rxeq top.
0x1404 COMRXEQ_R004 reset 0x1F01FAC6 — The comrxeq_004 register
  [31:24] COMRXEQ_MS_INIT_CTRL_7_0 — COMRXEQ mid speed initial calibration control [0] Adapt RXEQ stage 0 during initial mid speed cal [1] Adapt RXEQ stage 1 [2] Adapt RXEQ stage 2 [3] Adapt RXEQ stage 3 [4] Adapt RXEQ stage 4 [5] Adapt RXEQ stage 5 [6] Adapt RXEQ stage 6 [7] Adapt RXEQ stage 7 ...
  [23:16] COMRXEQ_LS_INIT_CTRL_7_0 — COMRXEQ low speed initial calibration control [0] Adapt RXEQ stage 0 during initial low speed cal [1] Adapt RXEQ stage 1 [2] Adapt RXEQ stage 2 [3] Adapt RXEQ stage 3 [4] Adapt RXEQ stage 4 [5] Adapt RXEQ stage 5 [6] Adapt RXEQ stage 6 [7] Adapt RXEQ stage 7 ...
0x1408 COMRXEQ_R008 reset 0xFF — The comrxeq_008 register
  [31:24] CSR_RXEQ_CONT_RUN_RATE3_O — This register mentions which blocks to be adapted during continuous calibration in RATE3, 1: calibration 0: load only
  [23:16] CSR_RXEQ_CONT_RUN_RATE2_O — This register mentions which blocks to be adapted during continuous calibration in RATE2, 1: calibration 0: load only
  [15:8] CSR_RXEQ_CONT_RUN_RATE1_O — This register mentions which blocks to be adapted during continuous calibration in RATE1, 1: calibration 0: load only.
  [7:0] COMRXEQ_HS_INIT_CAL_7_0 — COMRXEQ high speed initial calibration control [0] Adapt RXEQ stage 0 during initial high speed cal [1] Adapt RXEQ stage 1 [2] Adapt RXEQ stage 2 [3] Adapt RXEQ stage 3 [4] Adapt RXEQ stage 4 [5] Adapt RXEQ stage 5 [6] Adapt RXEQ stage 6 [7] Adapt RXEQ stage 7 ...
0x140C COMRXEQ_R00C reset 0x1FF1F01 — The comrxeq_00c register
  [23:16] COMRXEQ_HS_RECAL_CTRL_7_0 — COMRXEQ high speed recalibration control [0] Re-adapt RXEQ stage 0 during high speed recalibration [1] Re-adapt RXEQ stage 1 [2] Re-adapt RXEQ stage 2 [3] Re-adapt RXEQ stage 3 [4] Re-adapt RXEQ stage 4 [5] Re-adapt RXEQ stage 5 [6] Re-adapt RXEQ stage 6 [7] Re-adapt RXEQ stage 7 ...
  [15:8] COMRXEQ_MS_RECAL_CTRL_7_0 — COMRXEQ mid speed recalibration control [0] Re-adapt RXEQ stage 0 during mid speed recalibration [1] Re-adapt RXEQ stage 1 [2] Re-adapt RXEQ stage 2 [3] Re-adapt RXEQ stage 3 [4] Re-adapt RXEQ stage 4 [5] Re-adapt RXEQ stage 5 [6] Re-adapt RXEQ stage 6 [7] Re-adapt RXEQ stage 7 ...
  [7:0] COMRXEQ_LS_RECAL_CTRL_7_0 — COMRXEQ low speed recalibration control [0] Re-adapt RXEQ stage 0 during low speed recalibration [1] Re-adapt RXEQ stage 1 [2] Re-adapt RXEQ stage 2 [3] Re-adapt RXEQ stage 3 [4] Re-adapt RXEQ stage 4 [5] Re-adapt RXEQ stage 5 [6] Re-adapt RXEQ stage 6 [7] Re-adapt RXEQ stage 7 ...
0x141C COMRXEQ_R01C reset 0xA9001F00 — The comrxeq_01c register
  [15:12] COMRXEQ_CTRL4_3_0 — COMRXEQ control 4 register [3:0]
  [11:8] COMRXEQ_CTRL3_3_0 — COMRXEQ control 3 register [3:0]
  [5] COMRXEQ_CTRL2 — COMRXEQ control 2 register
  [3] COMRXEQ_HS_CONT_CAL_CTRL1 — COMRXEQ high speed continuous calibration control 1 register
  [2] COMRXEQ_MS_CONT_CAL_CTRL1 — COMRXEQ mid speed continuous calibration control 1 register
  [1] COMRXEQ_LS_CONT_CAL_CTRL1 — COMRXEQ low speed continuous calibration control 1 register
  [0] COMRXEQ_CTRL1 — COMRXEQ control 1 register
0x1428 COMRXEQ_R028 reset 0x8FFFF06 — The comrxeq_028 register
  [30] COMRXEQ_CTRL9 — COMRXEQ control 9 register
  [29] COMRXEQ_CTRL8 — COMRXEQ control 8 register
  [28] COMRXEQ_CTRL7 — COMRXEQ control 7 register
  [27:26] COMRXEQ_CTRL6_1_0 — COMRXEQ control 6 register [1:0]
  [25:24] COMRXEQ_CTRL5_1_0 — COMRXEQ control 5 register [1:0]
0x1434 COMRXEQ_R034 reset 0x1120707 — The comrxeq_034 register
  [24] COMRXEQ_CTRL12 — COMRXEQ control 12 register
  [20:19] COMRXEQ_CTRL11_2_0 — COMRXEQ control 11 register [1:0]
  [18:16] COMRXEQ_CTRL10_2_0 — COMRXEQ control 10 register [2:0]
  [12:11] CSR_GEN2_GAIN_START_VAL_O — Start value for GAIN Gen2 rate
  [10:8] CSR_GEN2_ATT_START_VAL_O — Start value for ATT adaptation Gen2 rate
  [4:3] CSR_GEN1_GAIN_START_VAL_O — Start value for GAIN Gen1 rate
  [2:0] CSR_GEN1_ATT_START_VAL_O — Start value for ATT adaptation for Gen1 rate
0x143C COMRXEQ_R03C reset 0x20200043 — The comrxeq_03c register
  [14:8] COMRXEQ_PATT_CTRL1_6_0 — COMRXEQ pattern control 1 register [6:0]
0x1444 COMRXEQ_R044 reset 0x40014093 — The comrxeq_044 register
  [7] COMRXEQ_CTRL13 — COMRXEQ control 13 register
  [6] COMRXEQ_PATT_CTRL4 — COMRXEQ pattern control 4 register
  [5] COMRXEQ_PATT_CTRL3 — COMRXEQ pattern control 3 register
  [4] COMRXEQ_PATT_CTRL2 — COMRXEQ pattern control 2 register
  [3:0] COMRXEQ_START_CTRL1_3_0 — COMRXEQ start value control 1 register [3:0]
0x1448 COMRXEQ_R048 reset 0x40004095 — The comrxeq_048 register
  [23:16] COMRXEQ_PATT_CTRL5_7_0 — COMRXEQ pattern control 5 register [7:0]
  [3:0] CSR_BSTADAPT_GEN2_BOOST_START_O — Edge Based Boost Start value for Gen2 rate
0x144C COMRXEQ_R04C reset 0x9C — The comrxeq_04c register
  [7] COMRXEQ_CTRL16 — COMRXEQ control 16 register
  [6] COMRXEQ_CTRL15 — COMRXEQ control 15 register
  [5] COMRXEQ_PATT_CTRL5_8 — COMRXEQ pattern control 5 register [8]
  [4] COMRXEQ_PATT_CTRL6 — COMRXEQ pattern control 6 register
  [3:0] COMRXEQ_CTRL14_3_0 — COMRXEQ control 14 register [3:0]
0x1458 COMRXEQ_R058 reset 0x43602000 — The comrxeq_058 register
  [6:0] COMRXEQ_PATT_CTRL7_6_0 — COMRXEQ pattern control 7 register [6:0]
0x1460 COMRXEQ_R060 reset 0x7F200060 — The comrxeq_060 register
  [30:24] COMRXEQ_PATT_CTRL8_6_0 — COMRXEQ pattern control 8 register [6:0]
0x1464 COMRXEQ_R064 reset 0x436F2043 — The comrxeq_064 register
  [30:24] COMRXEQ_PATT_CTRL11_6_0 — COMRXEQ pattern control 11 register [6:0]
  [22:16] COMRXEQ_PATT_CTRL10_6_0 — COMRXEQ pattern control 10 register [6:0]
  [6:0] COMRXEQ_PATT_CTRL9_6_0 — COMRXEQ pattern control 9 register [6:0]
0x1470 COMRXEQ_R070 reset 0x20007F80 — The comrxeq_070 register
  [22:16] COMRXEQ_PATT_CTRL12_6_0 — COMRXEQ pattern control 12 register [6:0]
0x1474 COMRXEQ_R074 reset 0x8020006F — The comrxeq_074 register
  [14:8] COMRXEQ_PATT_CTRL13_6_0 — COMRXEQ pattern control 13 register [6:0]
0x1484 COMRXEQ_R084 reset 0x3F8FFF00 — The comrxeq_084 register
  [23:20] COMRXEQ_CTRL18_3_0 — COMRXEQ control 18 register [3:0]
  [19:16] COMRXEQ_CTRL17_3_0 — COMRXEQ control 17 register [3:0]
0x1490 COMRXEQ_R090 reset 0x4023FF — The comrxeq_090 register
  [n-11] COMRXEQ_CTRL{n} (n=19..24) — COMRXEQ control {n} register
0x1494 COMRXEQ_R094 reset 0x50808000 — The comrxeq_094 register
  [31:24] COMRXEQ_CTRL25_7_0 — COMRXEQ control 25 register [7:0]
  [23:16] CSR_DFE_GEN2_TAP_START_VAL_O — Start value for DFE tap adaptation for Gen2 rate
  [15:8] CSR_DFE_GEN1_TAP_START_VAL_O — Start value for DFE tap adaptation for Gen1 rate
0x1498 COMRXEQ_R098 reset 0x40FF1F01 — The comrxeq_098 register
  [23:16] COMRXEQ_HS_RCHANGE_CTRL_7_0 — COMRXEQ high speed rate change calibration control [0] Adapt RXEQ stage 0 during high speed rate change [1] Adapt RXEQ stage 1 ... [2] Adapt RXEQ stage 2 ... [3] Adapt RXEQ stage 3 ... [4] Adapt RXEQ stage 4 ... [5] Adapt RXEQ stage 5 ... [6] Adapt RXEQ stage 6 ... [7] Adapt RXEQ stage 7 ...
  [15:8] CSR_RXEQ_RATE_CHANGE_CAL_RUN_RATE2_O — COMRXEQ mid speed rate change calibration control [0] Adapt RXEQ stage 0 during mid speed rate change [1] Adapt RXEQ stage 1 ... [2] Adapt RXEQ stage 2 ... [3] Adapt RXEQ stage 3 ... [4] Adapt RXEQ stage 4 ... [5] Adapt RXEQ stage 5 ... [6] Adapt RXEQ stage 6 ... [7] Adapt RXEQ stage 7...
  [7:0] CSR_RXEQ_RATE_CHANGE_CAL_RUN_RATE1_O — COMRXEQ low speed rate change calibration control [0] Adapt RXEQ stage 0 during low speed rate change [1] Adapt RXEQ stage 1 ... [2] Adapt RXEQ stage 2 ... [3] Adapt RXEQ stage 3 ... [4] Adapt RXEQ stage 4 ... [5] Adapt RXEQ stage 5 ... [6] Adapt RXEQ stage 6 ... [7] Adapt RXEQ stage 7...
0x1FC0 MOD_VER ro reset 0x4EBB6100 — The Module and Version Register identifies the module identifier and revision of the SERDES module.
  [31:16] MODULE_ID — SERDES module ID.
  [15:11] RTL_VERSION
  [10:8] MAJOR_REVISION
  [7:6] CUSTOM_REVISION
  [5:0] MINOR_REVISION
0x1FD0 SERDES_CTRL — Sets the SERDES control state.
  [29] POR_EN — The POR_EN allows the system to place the SERDES in a reset state. Accesses to the SERDES registers are ignored.
0x1FD4 LANE_PLL_STS ro reset 0x80000000 — The Lane and PLL Status register is used to indicate the current configuration of the REFCLK distribution and Lane Mux selection.
  [31] PLL0_PWR_ON — Indicates the state of the PLL0 REFCLK supplies. 0 - REFCLK power is off 1 - REFCLK power is on
  [27] PLL0_SEL_EXT — Indicates the chaining for the right side will be opposite of the PLL0_CHAIN_EN field used for the left chaining. 0 - Chaining for left and right will match PLL0_CHAIN_EN field. 1 - Chain left is PLL0_CHAIN_EN field and chain right is !PLL0_CHAIN_EN field.
  [26] PLL0_LEFT_SEL — Indicates the REFCLK source used for PLL0. This bit indicates that the left REFCLK input is used for the PLL0. When both PLL0_LEFT_SEL and PLL0_RIGHT_SEL are zero, the REFCLK pads are used for the PLL0.
  [25] PLL0_CHAIN_EN — Indicates the REFCLK chaining is enabled. 0 - REFCLK right and left are driven from the REFCLK pads of this Serdes 1 - REFCLK right or left is driven from left or right respectively.
  [24] PLL0_RIGHT_SEL — Indicates the REFCLK source used for PLL0. This bit indicates that the right REFCLK input is used for the PLL0. When both PLL0_LEFT_SEL and PLL0_RIGHT_SEL are zero, the REFCLK pads are used for the PLL0.
  [3] LANE0_PLL_LOCK — Indicates that the lane 0 tx clock is valid.
  [2] LANE0_RST_ISO — Indicates that the selected IF has the Lane 0 reset isolation signal set.
  [1:0] LANE0_IP_SEL — Indicates which interface is used for lane 0. See , Interface Selection
0x1FD8 SERDES_FEATURE ro reset 0x1 — The SERDES Feature register contains the features of the SERDES.
  [2:0] LANES — Indicates the number of lanes in this serdes
0x1FE0 LANEXCTL_STS access per field — The lane x control and status provides the ability to override SERDES configuration settings. It is mainly provided for test, but sometimes used for mission setup as well.
  [31] TX0_ENABLE_OVL rw — The Tx Enable Overlay bit, when set allows the Tx Enable Value to override the CFGTX.Enable input.
  [30:29] TX0_ENABLE_VAL rw — The Tx Enable Value when used allows the Tx lane to be placed in a 0 - Disable state. 1 - Sleep state. 2 - Snooze state. 3 - Enabled state.
  [28] TX0_RATE_OVL rw — The Tx Rate Overlay bit, when set allows the Tx Rate Value to override the CFGTX.Rate input.
  [27:26] TX0_RATE_VAL rw — The Tx Rate Value when used allows the Tx lane to be placed into 0 - Full Rate mode. 1 - Half Rate mode. 2 - Quarter Rate mode.
  [25] TX0_IDLE_OVL rw — The Tx Idle Overlay bit, when set allows the Tx Idle Value to override the CFGTX.Idle input.
  [24] TX0_IDLE_VAL rw — The Tx Idle Value, when used allows the Tx lane to be placed electrical Idle state in non Pipe Interface mode.
  [23] TX0_WIDTH_OVL rw — The Tx Width Overlay bit, when set allows the Tx Width Value to override the CFGTX.Width input.
  [22:21] TX0_WIDTH_VAL rw — The Tx Width Value, when used allows the Tx lane to be placed into 0 - 10 bit mode 1 - 16 bit mode 2 - 20 bit mode 3 - 40 bit mode This field is ignored in Pipe Interface Mode
  [15] RX0_ENABLE_OVL rw — The Rx Enable Overlay bi,t when set allows the Rx Enable Value to override the CFGRX.Enable input.
  [14:13] RX0_ENABLE_VAL rw — The Rx Enable Valu,e when used allows the Rx lane to be placed in a 0 - Disable state. 1 - Sleep state. 2 - Snooze state. 3 - Enabled state.
  [12] RX0_RATE_OVL rw — The Rx Rate Overlay bit, when set allows the Rx Rate Value to override the CFGRX.Rate input.
  [11:10] RX0_RATE_VAL rw — The Rx Rate Value when used allows the Rx lane to be placed into 0 - Full Rate mode. 1 - Half Rate mode. 2 - Quarter Rate mode.
  [9] RX0_POLARITY_OVL rw — The Rx Polarity Overlay bit, when set allows the Rx Polarity Value to override the CFGRX.Polarity input.
  [8] RX0_POLARITY_VAL rw — The Rx Polarity Value, when used allows the lane Rx Polarity to be inverted.
  [7] RX0_ALIGN_OVL rw — The Rx Align Overlay bit, when set allows the Rx Align Value to override the CFGRX.Align input.
  [6] RX0_ALIGN_VAL rw — The Rx Align Value, when used allows the Rx lane to align to K28.1, K28.5 and K28.7 characters otherwise known as Comma Characters.
  [5] RX0_WIDTH_OVL rw — The Rx Width Overlay bit, when set allows the Rx Width Value to override the CFGRX.Width input.
  [4:3] RX0_WIDTH_VAL rw — The Rx Width Value when used allows the Rx lane to be placed into 0 - 10-bit mode 1 - 16-bit mode 2 - 20-bit mode 3 - 40-bit mode This field is ignored in Pipe Interface Mode
  [1] RX0_OK ro — The Rx OK indicate that the lane is in a functional state.
  [0] RX0_LOSS ro — The Rx Signal Loss Indicates that the data has not been detected or the CDR is not locked.
0x1FF4 PLL_CTRL access per field — The PLL Control register provides the ability to override the PLL state and control events for debug purposes.
  [31] PLL_ENABLE_OVL rw — The PLL Enable Overlay bit, when set allows the PLL Enable Value to override the CFGPLL.Enable input.
  [30:29] PLL_ENABLE_VAL rw — The PLL Enable Value when used allows the PLL to be placed in a 0 - Disable state. 1 - Sleep state. 2 - Snooze state. 3 - Enabled state.
  [28] PLL_OK ro — The PLL Ok indicate that the transmit clocks are valid and the PLL circuits are ready for use.
  [17] LN_WAFTER_OK rw — The LN_WAFTER_OK field will cause the lane OK indication to be Blocked until the LN0_CONT_OK is set. This allows code to run after the lane OK but before the hardware can use the lane.
  [16] LN_WAFTER_SD rw — The LN_WAFTER_SD field will cause the Rx signal indication to be Blocked until the LN0_CONT_SD is set. This allows code to run after signal detect but before the hardware can use the data.
  [12] LN0_CONT_OK rw — The LN0_CONT_OK allows the Blocked lane OK for lane 0 to now pass to the controlling PCS IP. This bit is auto cleared when LN0_OK_STATE is driven inactive.
  [8] LN0_OK_STATE ro — The LN0_OK_STATE indicate the current state of the lane OK signal for lane 0.
  [4] LN0_CONT_SD rw — The LN0_CONT_SD allows the Blocked signal detect for lane 0 to now pass to the controlling PCS IP. This bit is auto cleared when LN0_SD_STATE is driven inactive.
  [0] LN0_SD_STATE ro — The LN0_SD_STATE indicate the current state of the signal detect signal for lane 0.
0x1FF8 COMMA_LINK_DELAY ro — The Comma Link Delay register defines the added delay due to comma alignment for the SERDES lanes. This value should be added to the receive time stamp to accurately time stamp the packet arrival. For a 1G link the value is 800pS per bit. This value may change any time the link is established.
  [7:0] LANE0_CDELAY — Defines the number of network bits the comma aligner has added to the fixed delay of the PCS/PMA layer for lane 0.
0x1FFC CMU_WAIT reset 0x50124F8 — The CMU Wait is used to create a 150 micro second delay between the completion of the SERDES configuration writes and activating the SERDES CMU logic allowing for supplies to settle.
  [31:24] IDDQ_CNT — Defines the number of clock cycles times 256 between pll_enable and cmu_master_cdn being set and the cmu_iddq going low.
  [23:20] PHAN_VAL — Defines the number of ~i(WAIT_VAL+1)*~i(PHAN_VAL+1) clock cycles between CMU Reset and when the phantom CMU_OK is generated. This allows the Serdes to start using valid clocks. The Phantom CMU_OK is used in Pipe mode. If this field is 0, the Phantom CMU_OK is equal to the actual CMU_OK.
  [16:0] WAIT_VAL — Defines the number of clock cycles between writing to the CMU Reset register and cmu_reset_i activation. The value should be 150 µs or more.
